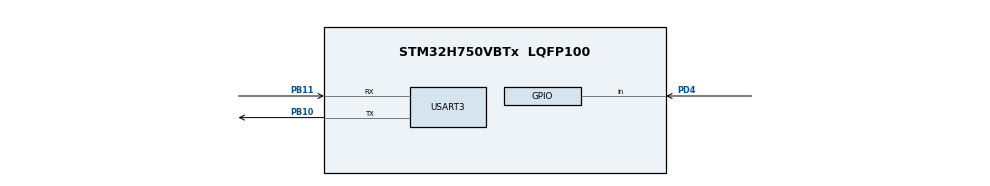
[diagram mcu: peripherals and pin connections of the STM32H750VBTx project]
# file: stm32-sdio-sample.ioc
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CORTEX_M7.BaseAddress_S-Cortex_Memory_Protection_Unit_Region1_Settings_S=0x10000
CORTEX_M7.Enable_S-Cortex_Memory_Protection_Unit_Region1_Settings_S=MPU_REGION_ENABLE
CORTEX_M7.Size_S-Cortex_Memory_Protection_Unit_Region1_Settings_S=MPU_REGION_SIZE_512KB
CORTEX_M7.default_mode_Activation=1
FREERTOS.Mutexes01=printfMutex,Dynamic,NULL,Available
FREERTOS.Tasks01=task1,24,512,StartTask1,Default,NULL,Dynamic,NULL,NULL;task2,24,512,StartTask2,Default,NULL,Dynamic,NULL,NULL;task3,24,512,StartTask3,Default,NULL,Dynamic,NULL,NULL
FREERTOS.configCHECK_FOR_STACK_OVERFLOW=2
FREERTOS.configRECORD_STACK_HIGH_ADDRESS=1
FREERTOS.configTICK_RATE_HZ=100
FREERTOS.configUSE_TICK_HOOK=0
Mcu.Family=STM32H7
Mcu.Name=STM32H750VBTx
Mcu.Package=LQFP100
NVIC.PriorityGroup=NVIC_PRIORITYGROUP_4
NVIC.TIM1_UP_IRQn=true\:15\:0\:false\:false\:true\:false\:false\:true\:true
NVIC.TimeBase=TIM1_UP_IRQn
NVIC.TimeBaseIP=TIM1
PA13\ (JTMS/SWDIO).Mode=Serial_Wire
PA13\ (JTMS/SWDIO).Signal=DEBUG_JTMS-SWDIO
PA14\ (JTCK/SWCLK).Mode=Serial_Wire
PA14\ (JTCK/SWCLK).Signal=DEBUG_JTCK-SWCLK
PB10.Mode=Asynchronous
PB10.Signal=USART3_TX
PB11.Mode=Asynchronous
PB11.Signal=USART3_RX
PD4.Signal=GPIO_Input
ProjectManager.HeapSize=0x200
ProjectManager.StackSize=0x400
ProjectManager.TargetToolchain=CMake
RCC.ADCFreq_Value=129000000
RCC.APB1Freq_Value=32000000
RCC.APB2Freq_Value=64000000
RCC.APB3Freq_Value=64000000
RCC.APB4Freq_Value=64000000
RCC.CortexFreq_Value=64000000
RCC.D2PPRE1=RCC_APB1_DIV2
RCC.DIVM1=4
RCC.DIVN1=9
RCC.DIVQ1=3
RCC.HCLKFreq_Value=64000000
RCC.PLLFRACN=3072
RCC.SYSCLKFreq_VALUE=64000000
RCC.USBFreq_Value=50000000
USART3.VirtualMode-Asynchronous=VM_ASYNC
VP_FREERTOS_VS_CMSIS_V2.Mode=CMSIS_V2
VP_MEMORYMAP_VS_MEMORYMAP.Mode=CurAppReg
VP_SYS_VS_tim1.Mode=TIM1
board=custom

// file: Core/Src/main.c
/* USER CODE BEGIN Header */
/**
  ******************************************************************************
  * @file           : main.c
  * @brief          : Main program body
  ******************************************************************************
  * @attention
  *
  * Copyright (c) 2026 STMicroelectronics.
  * All rights reserved.
  *
  * This software is licensed under terms that can be found in the LICENSE file
  * in the root directory of this software component.
  * If no LICENSE file comes with this software, it is provided AS-IS.
  *
  ******************************************************************************
  */
/* USER CODE END Header */
#include "main.h"
#include "FreeRTOS.h"
#include "cmsis_os2.h"
#include "usart.h"
#include "gpio.h"

/* USER CODE BEGIN Includes */
#include <stdio.h>
#include <logger.h>
//#include "utils.h"
/* USER CODE END Includes */

/* USER CODE BEGIN PV */
volatile int ok_cnt = 0;
volatile int error_cnt = 0;
volatile int busy_cnt = 0;
volatile int timeout_cnt = 0;

/* USER CODE END PV */

void SystemClock_Config(void);
static void MPU_Config(void);
void MX_FREERTOS_Init(void);
/* USER CODE BEGIN PFP */
//extern void initialise_monitor_handles(void);
/* USER CODE END PFP */

/* USER CODE BEGIN 0 */

int _write(int file, char *ptr, int len)
{
    HAL_StatusTypeDef res;
    res = HAL_UART_Transmit(&huart3, (uint8_t *)ptr, len, HAL_MAX_DELAY);
    switch (res) {
      case HAL_OK: ok_cnt++; break;
      case HAL_ERROR: error_cnt++; break;
      case HAL_BUSY: busy_cnt++; break;
      case HAL_TIMEOUT: timeout_cnt++; break;
    }
    return len;
}

/* USER CODE END 0 */

int main(void)
{

  /* USER CODE BEGIN 1 */
//	initialise_monitor_handles();
  /* USER CODE END 1 */

  /* MPU Configuration--------------------------------------------------------*/
  MPU_Config();

  /* MCU Configuration--------------------------------------------------------*/

  /* Reset of all peripherals, Initializes the Flash interface and the Systick. */
  HAL_Init();

  /* Configure the system clock */
  SystemClock_Config();

  /* Initialize all configured peripherals */
  MX_GPIO_Init();
  MX_USART3_UART_Init();
  /* USER CODE BEGIN 2 */
//  HAL_SD_CardInfoTypeDef cardInfo;
//  if (HAL_SD_GetCardInfo(&hsd1, &cardInfo) == HAL_OK)
//  {
//	  printf("Card Speed: %lu\n", cardInfo.CardSpeed);
//  }
//
//  Test_SD_Card();
  /* USER CODE END 2 */

  /* Init scheduler */
  osKernelInitialize();  /* Call init function for freertos objects (in cmsis_os2.c) */
  MX_FREERTOS_Init();

  /* Start scheduler */
  osKernelStart();

  /* We should never get here as control is now taken by the scheduler */

  /* Infinite loop */
  while (1)
  {

  }
}

void SystemClock_Config(void)
{
  RCC_OscInitTypeDef RCC_OscInitStruct = {0};
  RCC_ClkInitTypeDef RCC_ClkInitStruct = {0};

  /** Supply configuration update enable
  */
  HAL_PWREx_ConfigSupply(PWR_LDO_SUPPLY);

  /** Configure the main internal regulator output voltage
  */
  __HAL_PWR_VOLTAGESCALING_CONFIG(PWR_REGULATOR_VOLTAGE_SCALE3);

  while(!__HAL_PWR_GET_FLAG(PWR_FLAG_VOSRDY)) {}

  /** Initializes the RCC Oscillators according to the specified parameters
  * in the RCC_OscInitTypeDef structure.
  */
  RCC_OscInitStruct.OscillatorType = RCC_OSCILLATORTYPE_HSI;
  RCC_OscInitStruct.HSIState = RCC_HSI_DIV1;
  RCC_OscInitStruct.HSICalibrationValue = RCC_HSICALIBRATION_DEFAULT;
  RCC_OscInitStruct.PLL.PLLState = RCC_PLL_NONE;
  if (HAL_RCC_OscConfig(&RCC_OscInitStruct) != HAL_OK)
  {
    Error_Handler();
  }

  /** Initializes the CPU, AHB and APB buses clocks
  */
  RCC_ClkInitStruct.ClockType = RCC_CLOCKTYPE_HCLK|RCC_CLOCKTYPE_SYSCLK
                              |RCC_CLOCKTYPE_PCLK1|RCC_CLOCKTYPE_PCLK2
                              |RCC_CLOCKTYPE_D3PCLK1|RCC_CLOCKTYPE_D1PCLK1;
  RCC_ClkInitStruct.SYSCLKSource = RCC_SYSCLKSOURCE_HSI;
  RCC_ClkInitStruct.SYSCLKDivider = RCC_SYSCLK_DIV1;
  RCC_ClkInitStruct.AHBCLKDivider = RCC_HCLK_DIV1;
  RCC_ClkInitStruct.APB3CLKDivider = RCC_APB3_DIV1;
  RCC_ClkInitStruct.APB1CLKDivider = RCC_APB1_DIV2;
  RCC_ClkInitStruct.APB2CLKDivider = RCC_APB2_DIV1;
  RCC_ClkInitStruct.APB4CLKDivider = RCC_APB4_DIV1;

  if (HAL_RCC_ClockConfig(&RCC_ClkInitStruct, FLASH_LATENCY_1) != HAL_OK)
  {
    Error_Handler();
  }
}

 /* MPU Configuration */

void MPU_Config(void)
{
  MPU_Region_InitTypeDef MPU_InitStruct = {0};

  /* Disables the MPU */
  HAL_MPU_Disable();

  /** Initializes and configures the Region and the memory to be protected
  */
  MPU_InitStruct.Enable = MPU_REGION_ENABLE;
  MPU_InitStruct.Number = MPU_REGION_NUMBER0;
  MPU_InitStruct.BaseAddress = 0x0;
  MPU_InitStruct.Size = MPU_REGION_SIZE_4GB;
  MPU_InitStruct.SubRegionDisable = 0x87;
  MPU_InitStruct.TypeExtField = MPU_TEX_LEVEL0;
  MPU_InitStruct.AccessPermission = MPU_REGION_NO_ACCESS;
  MPU_InitStruct.DisableExec = MPU_INSTRUCTION_ACCESS_DISABLE;
  MPU_InitStruct.IsShareable = MPU_ACCESS_SHAREABLE;
  MPU_InitStruct.IsCacheable = MPU_ACCESS_NOT_CACHEABLE;
  MPU_InitStruct.IsBufferable = MPU_ACCESS_NOT_BUFFERABLE;

  HAL_MPU_ConfigRegion(&MPU_InitStruct);

  /** Initializes and configures the Region and the memory to be protected
  */
  MPU_InitStruct.Number = MPU_REGION_NUMBER1;
  MPU_InitStruct.BaseAddress = 0x10000;
  MPU_InitStruct.Size = MPU_REGION_SIZE_512KB;
  MPU_InitStruct.SubRegionDisable = 0x0;
  MPU_InitStruct.DisableExec = MPU_INSTRUCTION_ACCESS_ENABLE;
  MPU_InitStruct.IsShareable = MPU_ACCESS_NOT_SHAREABLE;

  HAL_MPU_ConfigRegion(&MPU_InitStruct);
  /* Enables the MPU */
  HAL_MPU_Enable(MPU_PRIVILEGED_DEFAULT);

}

void HAL_TIM_PeriodElapsedCallback(TIM_HandleTypeDef *htim)
{
  if (htim->Instance == TIM1)
  {
    HAL_IncTick();
  }
}

void Error_Handler(void)
{
  __disable_irq();
  while (1)
  {
  }
}

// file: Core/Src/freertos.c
/* USER CODE BEGIN Header */
/**
  ******************************************************************************
  * File Name          : freertos.c
  * Description        : Code for freertos applications
  ******************************************************************************
  * @attention
  *
  * Copyright (c) 2026 STMicroelectronics.
  * All rights reserved.
  *
  * This software is licensed under terms that can be found in the LICENSE file
  * in the root directory of this software component.
  * If no LICENSE file comes with this software, it is provided AS-IS.
  *
  ******************************************************************************
  */
/* USER CODE END Header */

#include "FreeRTOS.h"
#include "task.h"
#include "main.h"
#include "FreeRTOS.h"
#include "cmsis_os2.h"

/* USER CODE BEGIN Includes */
#include <stdio.h>
#include "semphr.h"
#include "logger.h"
#include "usart.h"
/* USER CODE END Includes */

/* USER CODE BEGIN Variables */
// osMutexId_t printMutexHandle;
// const osMutexAttr_t printMutex_attributes = {
//   .name = "printMutex",
//   .attr_bits =  osMutexPrioInherit
// };

/* USER CODE END Variables */
/* Definitions for task1 */
osThreadId_t task1Handle;
const osThreadAttr_t task1_attributes = {
  .name = "task1",
  .stack_size = 512 * 4,
  .priority = (osPriority_t) osPriorityNormal,
};
/* Definitions for task2 */
osThreadId_t task2Handle;
const osThreadAttr_t task2_attributes = {
  .name = "task2",
  .stack_size = 512 * 4,
  .priority = (osPriority_t) osPriorityNormal,
};
/* Definitions for task3 */
osThreadId_t task3Handle;
const osThreadAttr_t task3_attributes = {
  .name = "task3",
  .stack_size = 512 * 4,
  .priority = (osPriority_t) osPriorityNormal,
};
/* Definitions for printfMutex */
osMutexId_t printfMutexHandle;
const osMutexAttr_t printfMutex_attributes = {
  .name = "printfMutex"
};

/* USER CODE BEGIN FunctionPrototypes */
void safe_printf(const char *str)
{
  osMutexAcquire(printfMutexHandle, osWaitForever);   // берём мьютекс
  printf("%s", str);
  fflush(stdout);
  osMutexRelease(printfMutexHandle);
  osThreadYield();
}

/* USER CODE END FunctionPrototypes */

void StartTask1(void *argument);
void StartTask2(void *argument);
void StartTask3(void *argument);

void MX_FREERTOS_Init(void); /* (MISRA C 2004 rule 8.1) */

/* Hook prototypes */
void vApplicationStackOverflowHook(xTaskHandle xTask, char *pcTaskName);

/* USER CODE BEGIN 4 */
void vApplicationStackOverflowHook(xTaskHandle xTask, char *pcTaskName)
{
  for (;;){}
   /* Run time stack overflow checking is performed if
   configCHECK_FOR_STACK_OVERFLOW is defined to 1 or 2. This hook function is
   called if a stack overflow is detected. */
}
/* USER CODE END 4 */

void MX_FREERTOS_Init(void) {
  /* Create the mutex(es) */
  /* creation of printfMutex */
  printfMutexHandle = osMutexNew(&printfMutex_attributes);

  /* Create the thread(s) */
  /* creation of task1 */
  task1Handle = osThreadNew(StartTask1, NULL, &task1_attributes);

  /* creation of task2 */
  task2Handle = osThreadNew(StartTask2, NULL, &task2_attributes);

  /* creation of task3 */
  task3Handle = osThreadNew(StartTask3, NULL, &task3_attributes);

  /* USER CODE BEGIN RTOS_THREADS */
  Logger_Init();

  /* add threads, ... */
  /* USER CODE END RTOS_THREADS */

}

void StartTask1(void *argument)
{
  /* USER CODE BEGIN StartTask1 */
  const char* TAG = "Task1";
  int i = 0;
  /* Infinite loop */
  for(;;)
  {
    LOG_I(TAG,"Working %d", i++);
  }
  /* USER CODE END StartTask1 */
}

void StartTask2(void *argument)
{
  /* USER CODE BEGIN StartTask2 */
  const char* TAG = "Task2";
  int i = 0;
  /* Infinite loop */
  for(;;)
  {
    LOG_I(TAG,"Working %d", i++);
  }
  /* USER CODE END StartTask2 */
}

void StartTask3(void *argument)
{
  /* USER CODE BEGIN StartTask3 */
  const char* TAG = "Task3";
  int i = 0;
  /* Infinite loop */
  for(;;)
  {
    LOG_I(TAG,"Working %d", i++);
  }
  /* USER CODE END StartTask3 */
}
